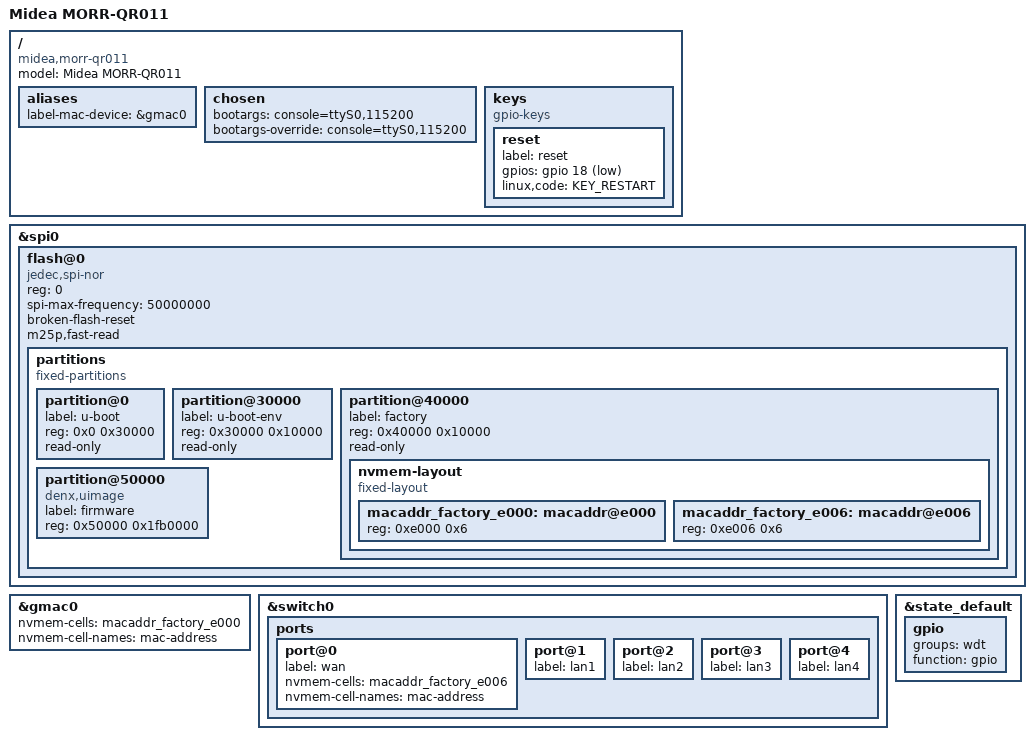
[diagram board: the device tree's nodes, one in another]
// SPDX-License-Identifier: GPL-2.0-or-later OR MIT

#include "mt7621.dtsi"

#include <dt-bindings/gpio/gpio.h>
#include <dt-bindings/input/input.h>

/ {
	compatible = "midea,morr-qr011", "mediatek,mt7621-soc";
	model = "Midea MORR-QR011";

	aliases {
		label-mac-device = &gmac0;
	};

	chosen {
		bootargs = "console=ttyS0,115200";
		bootargs-override = "console=ttyS0,115200";
	};

	keys {
		compatible = "gpio-keys";

		reset {
			label = "reset";
			gpios = <&gpio 18 GPIO_ACTIVE_LOW>;
			linux,code = <KEY_RESTART>;
		};
	};
};

&spi0 {
	status = "okay";

	flash@0 {
		compatible = "jedec,spi-nor";
		reg = <0>;
		spi-max-frequency = <50000000>;
		broken-flash-reset;
		m25p,fast-read;

		partitions {
			compatible = "fixed-partitions";
			#address-cells = <1>;
			#size-cells = <1>;

			partition@0 {
				label = "u-boot";
				reg = <0x0 0x30000>;
				read-only;
			};

			partition@30000 {
				label = "u-boot-env";
				reg = <0x30000 0x10000>;
				read-only;
			};

			partition@40000 {
				label = "factory";
				reg = <0x40000 0x10000>;
				read-only;

				nvmem-layout {
					compatible = "fixed-layout";
					#address-cells = <1>;
					#size-cells = <1>;

					macaddr_factory_e000: macaddr@e000 {
						reg = <0xe000 0x6>;
					};

					macaddr_factory_e006: macaddr@e006 {
						reg = <0xe006 0x6>;
					};
				};
			};

			partition@50000 {
				compatible = "denx,uimage";
				label = "firmware";
				reg = <0x50000 0x1fb0000>;
			};
		};
	};
};

&gmac0 {
	nvmem-cells = <&macaddr_factory_e000>;
	nvmem-cell-names = "mac-address";
};

&switch0 {
	ports {
		port@0 {
			status = "okay";
			label = "wan";
			nvmem-cells = <&macaddr_factory_e006>;
			nvmem-cell-names = "mac-address";
		};

		port@1 {
			status = "okay";
			label = "lan1";
		};

		port@2 {
			status = "okay";
			label = "lan2";
		};

		port@3 {
			status = "okay";
			label = "lan3";
		};

		port@4 {
			status = "okay";
			label = "lan4";
		};
	};
};

&state_default {
	gpio {
		groups = "wdt";
		function = "gpio";
	};
};
